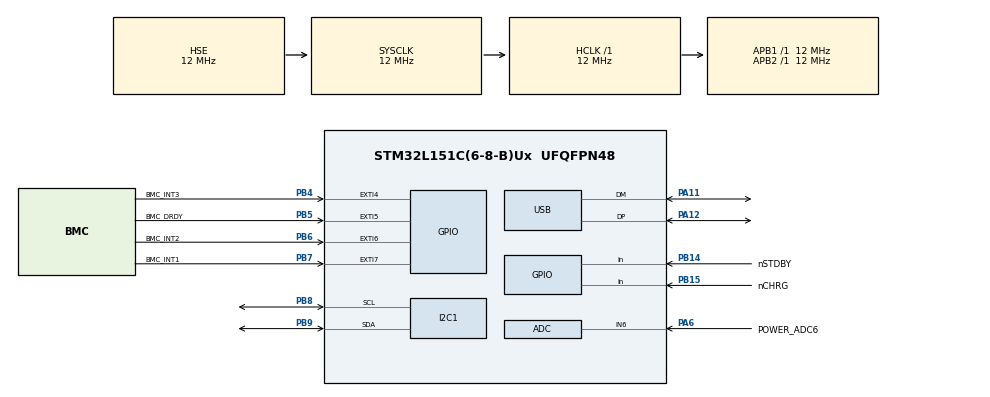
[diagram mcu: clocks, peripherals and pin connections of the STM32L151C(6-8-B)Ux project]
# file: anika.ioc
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ADC.Channel-0\#ChannelRegularConversion=ADC_CHANNEL_6
ADC.NbrOfConversionFlag=1
ADC.Rank-0\#ChannelRegularConversion=1
ADC.SamplingTime-0\#ChannelRegularConversion=ADC_SAMPLETIME_4CYCLES
I2C1.I2C_Mode=I2C_Fast
Mcu.Family=STM32L1
Mcu.Name=STM32L151C(6-8-B)Ux
Mcu.Package=UFQFPN48
NVIC.EXTI4_IRQn=true\:0\:0\:false\:false\:true
NVIC.EXTI9_5_IRQn=true\:0\:0\:false\:false\:true
NVIC.PriorityGroup=NVIC_PRIORITYGROUP_4
NVIC.USB_LP_IRQn=true\:0\:0\:false\:false\:true
PA11.Mode=Device
PA11.Signal=USB_DM
PA12.Mode=Device
PA12.Signal=USB_DP
PA13.Mode=Serial_Wire
PA13.Signal=SYS_JTMS-SWDIO
PA14.Mode=Serial_Wire
PA14.Signal=SYS_JTCK-SWCLK
PA6.GPIO_Label=POWER_ADC6
PA6.Mode=IN6
PA6.Signal=ADC_IN6
PB14.GPIO_Label=nSTDBY
PB14.Signal=GPIO_Input
PB15.GPIO_Label=nCHRG
PB15.Signal=GPIO_Input
PB4.GPIO_Label=BMC_INT3
PB4.Signal=GPXTI4
PB5.GPIO_Label=BMC_DRDY
PB5.Signal=GPXTI5
PB6.GPIO_Label=BMC_INT2
PB6.Signal=GPXTI6
PB7.GPIO_Label=BMC_INT1
PB7.Signal=GPXTI7
PB8.Mode=I2C
PB8.Signal=I2C1_SCL
PB9.Mode=I2C
PB9.Signal=I2C1_SDA
PC14-OSC32_IN.Mode=LSE-External-Oscillator
PC14-OSC32_IN.Signal=RCC_OSC32_IN
PC15-OSC32_OUT.Mode=LSE-External-Oscillator
PC15-OSC32_OUT.Signal=RCC_OSC32_OUT
PH0-OSC_IN.Mode=HSE-External-Oscillator
PH0-OSC_IN.Signal=RCC_OSC_IN
PH1-OSC_OUT.Mode=HSE-External-Oscillator
PH1-OSC_OUT.Signal=RCC_OSC_OUT
ProjectManager.HeapSize=0x200
ProjectManager.StackSize=0x400
ProjectManager.TargetToolchain=TrueSTUDIO
RCC.AHBFreq_Value=12000000
RCC.APB1Freq_Value=12000000
RCC.APB1TimFreq_Value=12000000
RCC.APB2Freq_Value=12000000
RCC.APB2TimFreq_Value=12000000
RCC.HCLKFreq_Value=12000000
RCC.HSE_VALUE=12000000
RCC.HSI_VALUE=16000000
RCC.MSI_VALUE=2097000
RCC.PLLMUL=RCC_PLL_MUL8
RCC.RTCClockSelection=RCC_RTCCLKSOURCE_LSE
RCC.SYSCLKFreq_VALUE=12000000
RCC.SYSCLKSource=RCC_SYSCLKSOURCE_HSE
RCC.USBOutput=48000000
RCC.VCOOutputFreq_Value=96000000
RTC.Format=RTC_FORMAT_BIN
USB_DEVICE.CLASS_NAME_FS=CDC
USB_DEVICE.USBD_HandleTypeDef=hUsbDeviceFS
USB_DEVICE.VirtualMode=Cdc
USB_DEVICE.VirtualModeFS=Cdc_FS
VP_ADC_TempSens_Input.Mode=IN-TempSens
VP_ADC_Vref_Input.Mode=IN-Vrefint
VP_RTC_VS_RTC_Activate.Mode=RTC_Enabled
VP_RTC_VS_RTC_Calendar.Mode=RTC_Calendar
VP_USB_DEVICE_VS_USB_DEVICE_CDC_FS.Mode=CDC_FS
board=anika

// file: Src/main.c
/**
  ******************************************************************************
  * File Name          : main.c
  * Description        : Main program body
  ******************************************************************************
  *
  * Copyright (c) 2016 STMicroelectronics International N.V.
  * All rights reserved.
  *
  * Redistribution and use in source and binary forms, with or without
  * modification, are permitted, provided that the following conditions are met:
  *
  * 1. Redistribution of source code must retain the above copyright notice,
  *    this list of conditions and the following disclaimer.
  * 2. Redistributions in binary form must reproduce the above copyright notice,
  *    this list of conditions and the following disclaimer in the documentation
  *    and/or other materials provided with the distribution.
  * 3. Neither the name of STMicroelectronics nor the names of other
  *    contributors to this software may be used to endorse or promote products
  *    derived from this software without specific written permission.
  * 4. This software, including modifications and/or derivative works of this
  *    software, must execute solely and exclusively on microcontroller or
  *    microprocessor devices manufactured by or for STMicroelectronics.
  * 5. Redistribution and use of this software other than as permitted under
  *    this license is void and will automatically terminate your rights under
  *    this license.
  *
  * THIS SOFTWARE IS PROVIDED BY STMICROELECTRONICS AND CONTRIBUTORS "AS IS"
  * AND ANY EXPRESS, IMPLIED OR STATUTORY WARRANTIES, INCLUDING, BUT NOT
  * LIMITED TO, THE IMPLIED WARRANTIES OF MERCHANTABILITY, FITNESS FOR A
  * PARTICULAR PURPOSE AND NON-INFRINGEMENT OF THIRD PARTY INTELLECTUAL PROPERTY
  * RIGHTS ARE DISCLAIMED TO THE FULLEST EXTENT PERMITTED BY LAW. IN NO EVENT
  * SHALL STMICROELECTRONICS OR CONTRIBUTORS BE LIABLE FOR ANY DIRECT, INDIRECT,
  * INCIDENTAL, SPECIAL, EXEMPLARY, OR CONSEQUENTIAL DAMAGES (INCLUDING, BUT NOT
  * LIMITED TO, PROCUREMENT OF SUBSTITUTE GOODS OR SERVICES; LOSS OF USE, DATA,
  * OR PROFITS; OR BUSINESS INTERRUPTION) HOWEVER CAUSED AND ON ANY THEORY OF
  * LIABILITY, WHETHER IN CONTRACT, STRICT LIABILITY, OR TORT (INCLUDING
  * NEGLIGENCE OR OTHERWISE) ARISING IN ANY WAY OUT OF THE USE OF THIS SOFTWARE,
  * EVEN IF ADVISED OF THE POSSIBILITY OF SUCH DAMAGE.
  *
  ******************************************************************************
  */
#include "main.h"
#include "stm32l1xx_hal.h"
#include "adc.h"
#include "i2c.h"
#include "rtc.h"
#include "usb_device.h"
#include "gpio.h"

/* USER CODE BEGIN Includes */
int workflow();
/* USER CODE END Includes */

/* USER CODE BEGIN PV */
/* Private variables ---------------------------------------------------------*/

/* USER CODE END PV */

void SystemClock_Config(void);
void Error_Handler(void);

/* USER CODE BEGIN PFP */
/* Private function prototypes -----------------------------------------------*/
/* USER CODE END PFP */

int main(void)
{

  /* MCU Configuration----------------------------------------------------------*/

  /* Reset of all peripherals, Initializes the Flash interface and the Systick. */
  HAL_Init();

  /* Configure the system clock */
  SystemClock_Config();

  /* Initialize all configured peripherals */
  MX_GPIO_Init();
  MX_ADC_Init();
  MX_I2C1_Init();
  MX_RTC_Init();
  MX_USB_DEVICE_Init();

  /* Infinite loop */
  while (1)
  {

  /* USER CODE BEGIN 3 */
      workflow();
  }
  /* USER CODE END 3 */

}

/** System Clock Configuration
*/
void SystemClock_Config(void)
{

  RCC_OscInitTypeDef RCC_OscInitStruct;
  RCC_ClkInitTypeDef RCC_ClkInitStruct;
  RCC_PeriphCLKInitTypeDef PeriphClkInit;

    /**Configure the main internal regulator output voltage
    */
  __HAL_PWR_VOLTAGESCALING_CONFIG(PWR_REGULATOR_VOLTAGE_SCALE1);

    /**Initializes the CPU, AHB and APB busses clocks
    */
  RCC_OscInitStruct.OscillatorType = RCC_OSCILLATORTYPE_HSI|RCC_OSCILLATORTYPE_HSE
                              |RCC_OSCILLATORTYPE_LSE;
  RCC_OscInitStruct.HSEState = RCC_HSE_ON;
  RCC_OscInitStruct.LSEState = RCC_LSE_ON;
  RCC_OscInitStruct.HSIState = RCC_HSI_ON;
  RCC_OscInitStruct.HSICalibrationValue = 16;
  RCC_OscInitStruct.PLL.PLLState = RCC_PLL_ON;
  RCC_OscInitStruct.PLL.PLLSource = RCC_PLLSOURCE_HSE;
  RCC_OscInitStruct.PLL.PLLMUL = RCC_PLL_MUL8;
  RCC_OscInitStruct.PLL.PLLDIV = RCC_PLL_DIV2;
  if (HAL_RCC_OscConfig(&RCC_OscInitStruct) != HAL_OK)
  {
    Error_Handler();
  }

    /**Initializes the CPU, AHB and APB busses clocks
    */
  RCC_ClkInitStruct.ClockType = RCC_CLOCKTYPE_HCLK|RCC_CLOCKTYPE_SYSCLK
                              |RCC_CLOCKTYPE_PCLK1|RCC_CLOCKTYPE_PCLK2;
  RCC_ClkInitStruct.SYSCLKSource = RCC_SYSCLKSOURCE_HSE;
  RCC_ClkInitStruct.AHBCLKDivider = RCC_SYSCLK_DIV1;
  RCC_ClkInitStruct.APB1CLKDivider = RCC_HCLK_DIV1;
  RCC_ClkInitStruct.APB2CLKDivider = RCC_HCLK_DIV1;

  if (HAL_RCC_ClockConfig(&RCC_ClkInitStruct, FLASH_LATENCY_0) != HAL_OK)
  {
    Error_Handler();
  }

  PeriphClkInit.PeriphClockSelection = RCC_PERIPHCLK_RTC;
  PeriphClkInit.RTCClockSelection = RCC_RTCCLKSOURCE_LSE;
  if (HAL_RCCEx_PeriphCLKConfig(&PeriphClkInit) != HAL_OK)
  {
    Error_Handler();
  }

    /**Configure the Systick interrupt time
    */
  HAL_SYSTICK_Config(HAL_RCC_GetHCLKFreq()/1000);

    /**Configure the Systick
    */
  HAL_SYSTICK_CLKSourceConfig(SYSTICK_CLKSOURCE_HCLK);

  /* SysTick_IRQn interrupt configuration */
  HAL_NVIC_SetPriority(SysTick_IRQn, 0, 0);
}

void Error_Handler(void)
{
  while(1)
  {
  }
}

/************************ (C) COPYRIGHT STMicroelectronics *****END OF FILE****/
